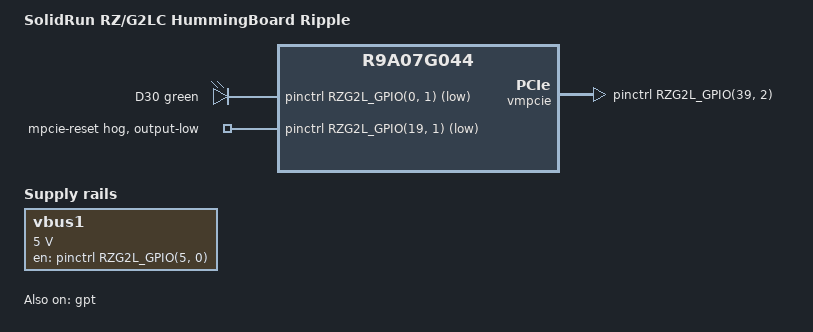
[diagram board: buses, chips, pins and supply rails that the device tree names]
// SPDX-License-Identifier: (GPL-2.0-only OR BSD-2-Clause)
/*
 * Copyright 2025 Josua Mayer <josua@solid-run.com>
 */

/dts-v1/;

#include "r9a07g044c2.dtsi"
#include "rzg2lc-sr-som.dtsi"
#include "rzg2l-hummingboard-pulse-common.dtsi"
#include "rzg2l-hummingboard-pulse-micro-hdmi.dtsi"

/ {
	compatible = "solidrun,rzg2lc-hummingboard-ripple", "solidrun,rzg2lc-sr-som",
		     "renesas,r9a07g044c2", "renesas,r9a07g044";
	model = "SolidRun RZ/G2LC HummingBoard Ripple";

	leds: leds {
		compatible = "gpio-leds";

		led-0 {
			color = <LED_COLOR_ID_GREEN>;
			default-state = "on";
			gpios = <&pinctrl RZG2L_GPIO(0, 1) GPIO_ACTIVE_LOW>;
			label = "D30";
		};
	};

	vbus1: regulator-vbus-1 {
		compatible = "regulator-fixed";
		regulator-name = "vbus1";
		regulator-max-microvolt = <5000000>;
		regulator-min-microvolt = <5000000>;
		gpios = <&pinctrl RZG2L_GPIO(5, 0) GPIO_ACTIVE_HIGH>;
		enable-active-high;
	};
};

&gpt {
	/* mikrobus header pwm pin is pwm channel 6 */
	pinctrl-0 = <&mikro_pwm_pins>;
	pinctrl-names = "default";
	status = "okay";
};

&hdmi {
	interrupts-extended = <&pinctrl RZG2L_GPIO(42, 2) IRQ_TYPE_EDGE_FALLING>;
	pd-gpios = <&pinctrl RZG2L_GPIO(40, 2) GPIO_ACTIVE_LOW>;
};

&hub_2_0 {
	reset-gpios = <&pinctrl RZG2L_GPIO(39, 1) GPIO_ACTIVE_LOW>;
};

&pinctrl {
	mpcie_rst_hog: mpcie-reset-hog {
		gpios = <RZG2L_GPIO(19, 1) GPIO_ACTIVE_LOW>;
		gpio-hog;
		line-name = "mpcie-reset";
		output-low;
	};

	mikro_pwm_pins: pinctrl-mikro-pwm-grp {
		pinmux = <RZG2L_PORT_PINMUX(41, 0, 4)>; /* GTIOC3A */
	};

	mikro_uart_pins: pinctrl-mikro-uart-grp {
		pinmux = <RZG2L_PORT_PINMUX(40, 1, 1)>, /* SCIF1_RXD */
			 <RZG2L_PORT_PINMUX(40, 0, 1)>; /* SCIF1_TXD */
	};

	usb0_vbus_pins: usb0-vbus {
		pinmux = <RZG2L_PORT_PINMUX(4, 0, 1)>; /* USB0_VBUSEN */
	};
};

&usb2_phy1 {
	vbus-supply = <&vbus1>;
};

&vmmc {
	gpios = <&pinctrl RZG2L_GPIO(18, 1) GPIO_ACTIVE_LOW>;
};

&vmpcie {
	/*
	 * G2LC SoM v1.2 moved this IO from J7-28 (CON4-12)
	 * to J7-18 (this regulator).
	 * There are no known users of CON4-12 and thus no need
	 * to differentiate here between SoM v1.1 and v1.2.
	 */
	gpios = <&pinctrl RZG2L_GPIO(39, 2) GPIO_ACTIVE_HIGH>;
};
